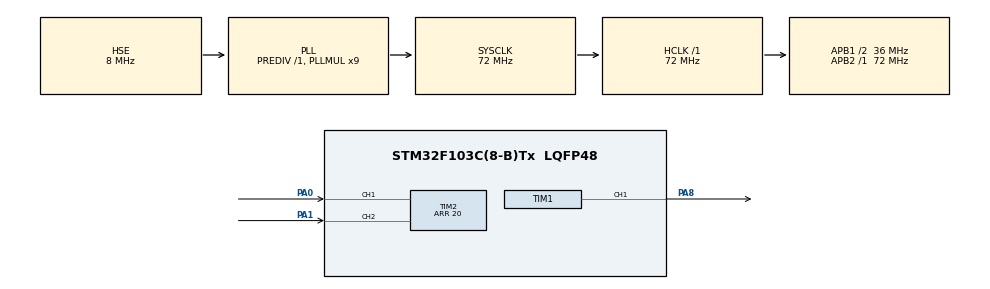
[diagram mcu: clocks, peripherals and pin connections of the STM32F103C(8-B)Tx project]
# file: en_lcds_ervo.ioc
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Mcu.Family=STM32F1
Mcu.Name=STM32F103C(8-B)Tx
Mcu.Package=LQFP48
NVIC.PriorityGroup=NVIC_PRIORITYGROUP_4
PA0-WKUP.Signal=S_TIM2_CH1_ETR
PA1.Signal=S_TIM2_CH2
PA13.Mode=Serial_Wire
PA13.Signal=SYS_JTMS-SWDIO
PA14.Mode=Serial_Wire
PA14.Signal=SYS_JTCK-SWCLK
PA8.Signal=S_TIM1_CH1
PD0-OSC_IN.Mode=HSE-External-Oscillator
PD0-OSC_IN.Signal=RCC_OSC_IN
PD1-OSC_OUT.Mode=HSE-External-Oscillator
PD1-OSC_OUT.Signal=RCC_OSC_OUT
ProjectManager.HeapSize=0x200
ProjectManager.StackSize=0x400
ProjectManager.TargetToolchain=STM32CubeIDE
RCC.AHBFreq_Value=72000000
RCC.APB1CLKDivider=RCC_HCLK_DIV2
RCC.APB1Freq_Value=36000000
RCC.APB1TimFreq_Value=72000000
RCC.APB2Freq_Value=72000000
RCC.APB2TimFreq_Value=72000000
RCC.HCLKFreq_Value=72000000
RCC.PLLMUL=RCC_PLL_MUL9
RCC.PLLSourceVirtual=RCC_PLLSOURCE_HSE
RCC.SYSCLKFreq_VALUE=72000000
RCC.SYSCLKSource=RCC_SYSCLKSOURCE_PLLCLK
RCC.USBFreq_Value=72000000
SH.S_TIM1_CH1.0=TIM1_CH1,PWM Generation1 CH1
SH.S_TIM2_CH1_ETR.0=TIM2_CH1,Encoder_Interface
SH.S_TIM2_CH2.0=TIM2_CH2,Encoder_Interface
TIM1.AutoReloadPreload=TIM_AUTORELOAD_PRELOAD_DISABLE
TIM1.Channel-PWM\ Generation1\ CH1=TIM_CHANNEL_1
TIM1.Period=19999
TIM1.Prescaler=72
TIM2.AutoReloadPreload=TIM_AUTORELOAD_PRELOAD_ENABLE
TIM2.EncoderMode=TIM_ENCODERMODE_TI1
TIM2.IC1Filter=10
TIM2.Period=20
VP_TIM1_VS_ClockSourceINT.Mode=Internal
board=custom

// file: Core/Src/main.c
/* USER CODE BEGIN Header */
/**
  ******************************************************************************
  * @file           : main.c
  * @brief          : Main program body
  ******************************************************************************
  * @attention
  *
  * Copyright (c) 2024 STMicroelectronics.
  * All rights reserved.
  *
  * This software is licensed under terms that can be found in the LICENSE file
  * in the root directory of this software component.
  * If no LICENSE file comes with this software, it is provided AS-IS.
  *
  ******************************************************************************
  */
/* USER CODE END Header */
#include "main.h"
#include <stdio.h>

/* USER CODE BEGIN PD */
#define counts_per_rev 20 //as we have 20 ticks in encoder and make the arr in ioc 20
/* USER CODE END PD */

TIM_HandleTypeDef htim1;
TIM_HandleTypeDef htim2;

/* USER CODE BEGIN PV */
Alcd_t lcd1 = {
		.Data_GPIO = GPIOA,
		.Data_GPIO_Start_Pin=2,
		.RS_GPIO= GPIOA,
		.RS_GPIO_Pin= GPIO_PIN_6,
		.EN_GPIO= GPIOA,
		.EN_GPIO_Pin= GPIO_PIN_7,
};
char degree_counter[20];
/* USER CODE END PV */

void SystemClock_Config(void);
static void MX_GPIO_Init(void);
static void MX_TIM1_Init(void);
static void MX_TIM2_Init(void);

/* USER CODE BEGIN 0 */
uint32_t degree_pwm(uint8_t degree_value );

/* USER CODE END 0 */

int main(void)
{

  /* MCU Configuration--------------------------------------------------------*/

  /* Reset of all peripherals, Initializes the Flash interface and the Systick. */
  HAL_Init();

  /* Configure the system clock */
  SystemClock_Config();

  /* Initialize all configured peripherals */
  MX_GPIO_Init();
  MX_TIM1_Init();
  MX_TIM2_Init();
  /* USER CODE BEGIN 2 */
  ///////************lcd config*****************
  Alcd_Init(&lcd1, 2, 0);
 // Alcd_PutAt(&lcd1,1,0,"HAzEM");
  Alcd_PutAt_n(&lcd1, 0, 0, "kiroo", Str_Len("kiroo"));
 // Alcd_Clear(&lcd1);
  ////////********encoder and servo config**************
    HAL_TIM_Encoder_Start(&htim2, TIM_CHANNEL_ALL); // Start the counter for the encoder
    HAL_TIM_PWM_Start(&htim1, TIM_CHANNEL_1); // For output to the servo
    __HAL_TIM_SET_COMPARE(&htim1, TIM_CHANNEL_1, 1500); // Set a duty cycle for the servo
    HAL_Delay(3000);

  /* USER CODE END 2 */

  /* Infinite loop */
  /* USER CODE BEGIN WHILE */
    while (1)
    {
        uint8_t encoder_counter = __HAL_TIM_GET_COUNTER(&htim2); // Get the counter of the encoder
        uint8_t degrees= (encoder_counter*180.0)/counts_per_rev;

        uint32_t pwm_val = degree_pwm(degrees); // Convert degrees to PWM value
        sprintf(degree_counter, "the angle %d", degrees);
          Alcd_PutAt_n(&lcd1, 0, 0,degree_counter , strlen(degree_counter));

       // __HAL_TIM_SET_COMPARE(&htim1, TIM_CHANNEL_1, pwm_val); // Set PWM value for servo
        htim1.Instance->CCR1 = pwm_val;
        HAL_Delay(100); // Delay for stability
        Alcd_Clear(&lcd1);
    }
    /* USER CODE END WHILE */

}

void SystemClock_Config(void)
{
  RCC_OscInitTypeDef RCC_OscInitStruct = {0};
  RCC_ClkInitTypeDef RCC_ClkInitStruct = {0};

  /** Initializes the RCC Oscillators according to the specified parameters
  * in the RCC_OscInitTypeDef structure.
  */
  RCC_OscInitStruct.OscillatorType = RCC_OSCILLATORTYPE_HSE;
  RCC_OscInitStruct.HSEState = RCC_HSE_ON;
  RCC_OscInitStruct.HSEPredivValue = RCC_HSE_PREDIV_DIV1;
  RCC_OscInitStruct.HSIState = RCC_HSI_ON;
  RCC_OscInitStruct.PLL.PLLState = RCC_PLL_ON;
  RCC_OscInitStruct.PLL.PLLSource = RCC_PLLSOURCE_HSE;
  RCC_OscInitStruct.PLL.PLLMUL = RCC_PLL_MUL9;
  if (HAL_RCC_OscConfig(&RCC_OscInitStruct) != HAL_OK)
  {
    Error_Handler();
  }

  /** Initializes the CPU, AHB and APB buses clocks
  */
  RCC_ClkInitStruct.ClockType = RCC_CLOCKTYPE_HCLK|RCC_CLOCKTYPE_SYSCLK
                              |RCC_CLOCKTYPE_PCLK1|RCC_CLOCKTYPE_PCLK2;
  RCC_ClkInitStruct.SYSCLKSource = RCC_SYSCLKSOURCE_PLLCLK;
  RCC_ClkInitStruct.AHBCLKDivider = RCC_SYSCLK_DIV1;
  RCC_ClkInitStruct.APB1CLKDivider = RCC_HCLK_DIV2;
  RCC_ClkInitStruct.APB2CLKDivider = RCC_HCLK_DIV1;

  if (HAL_RCC_ClockConfig(&RCC_ClkInitStruct, FLASH_LATENCY_2) != HAL_OK)
  {
    Error_Handler();
  }
}

static void MX_TIM1_Init(void)
{

  TIM_ClockConfigTypeDef sClockSourceConfig = {0};
  TIM_MasterConfigTypeDef sMasterConfig = {0};
  TIM_OC_InitTypeDef sConfigOC = {0};
  TIM_BreakDeadTimeConfigTypeDef sBreakDeadTimeConfig = {0};

  htim1.Instance = TIM1;
  htim1.Init.Prescaler = 72;
  htim1.Init.CounterMode = TIM_COUNTERMODE_UP;
  htim1.Init.Period = 19999;
  htim1.Init.ClockDivision = TIM_CLOCKDIVISION_DIV1;
  htim1.Init.RepetitionCounter = 0;
  htim1.Init.AutoReloadPreload = TIM_AUTORELOAD_PRELOAD_DISABLE;
  if (HAL_TIM_Base_Init(&htim1) != HAL_OK)
  {
    Error_Handler();
  }
  sClockSourceConfig.ClockSource = TIM_CLOCKSOURCE_INTERNAL;
  if (HAL_TIM_ConfigClockSource(&htim1, &sClockSourceConfig) != HAL_OK)
  {
    Error_Handler();
  }
  if (HAL_TIM_PWM_Init(&htim1) != HAL_OK)
  {
    Error_Handler();
  }
  sMasterConfig.MasterOutputTrigger = TIM_TRGO_RESET;
  sMasterConfig.MasterSlaveMode = TIM_MASTERSLAVEMODE_DISABLE;
  if (HAL_TIMEx_MasterConfigSynchronization(&htim1, &sMasterConfig) != HAL_OK)
  {
    Error_Handler();
  }
  sConfigOC.OCMode = TIM_OCMODE_PWM1;
  sConfigOC.Pulse = 0;
  sConfigOC.OCPolarity = TIM_OCPOLARITY_HIGH;
  sConfigOC.OCNPolarity = TIM_OCNPOLARITY_HIGH;
  sConfigOC.OCFastMode = TIM_OCFAST_DISABLE;
  sConfigOC.OCIdleState = TIM_OCIDLESTATE_RESET;
  sConfigOC.OCNIdleState = TIM_OCNIDLESTATE_RESET;
  if (HAL_TIM_PWM_ConfigChannel(&htim1, &sConfigOC, TIM_CHANNEL_1) != HAL_OK)
  {
    Error_Handler();
  }
  sBreakDeadTimeConfig.OffStateRunMode = TIM_OSSR_DISABLE;
  sBreakDeadTimeConfig.OffStateIDLEMode = TIM_OSSI_DISABLE;
  sBreakDeadTimeConfig.LockLevel = TIM_LOCKLEVEL_OFF;
  sBreakDeadTimeConfig.DeadTime = 0;
  sBreakDeadTimeConfig.BreakState = TIM_BREAK_DISABLE;
  sBreakDeadTimeConfig.BreakPolarity = TIM_BREAKPOLARITY_HIGH;
  sBreakDeadTimeConfig.AutomaticOutput = TIM_AUTOMATICOUTPUT_DISABLE;
  if (HAL_TIMEx_ConfigBreakDeadTime(&htim1, &sBreakDeadTimeConfig) != HAL_OK)
  {
    Error_Handler();
  }
  HAL_TIM_MspPostInit(&htim1);

}

static void MX_TIM2_Init(void)
{

  TIM_Encoder_InitTypeDef sConfig = {0};
  TIM_MasterConfigTypeDef sMasterConfig = {0};

  htim2.Instance = TIM2;
  htim2.Init.Prescaler = 0;
  htim2.Init.CounterMode = TIM_COUNTERMODE_UP;
  htim2.Init.Period = 20;
  htim2.Init.ClockDivision = TIM_CLOCKDIVISION_DIV1;
  htim2.Init.AutoReloadPreload = TIM_AUTORELOAD_PRELOAD_ENABLE;
  sConfig.EncoderMode = TIM_ENCODERMODE_TI1;
  sConfig.IC1Polarity = TIM_ICPOLARITY_RISING;
  sConfig.IC1Selection = TIM_ICSELECTION_DIRECTTI;
  sConfig.IC1Prescaler = TIM_ICPSC_DIV1;
  sConfig.IC1Filter = 10;
  sConfig.IC2Polarity = TIM_ICPOLARITY_RISING;
  sConfig.IC2Selection = TIM_ICSELECTION_DIRECTTI;
  sConfig.IC2Prescaler = TIM_ICPSC_DIV1;
  sConfig.IC2Filter = 0;
  if (HAL_TIM_Encoder_Init(&htim2, &sConfig) != HAL_OK)
  {
    Error_Handler();
  }
  sMasterConfig.MasterOutputTrigger = TIM_TRGO_RESET;
  sMasterConfig.MasterSlaveMode = TIM_MASTERSLAVEMODE_DISABLE;
  if (HAL_TIMEx_MasterConfigSynchronization(&htim2, &sMasterConfig) != HAL_OK)
  {
    Error_Handler();
  }

}

static void MX_GPIO_Init(void)
{

  /* GPIO Ports Clock Enable */
  __HAL_RCC_GPIOD_CLK_ENABLE();
  __HAL_RCC_GPIOA_CLK_ENABLE();

}

/* USER CODE BEGIN 4 */
/*uint32_t degree_pwm(uint32_t degree_value ){
	return ((degree_value*1000)/180)+1000;
};*/
uint32_t degree_pwm(uint8_t degree_value) {
    // Clamp the degree value to the range -90 to 90
   /* if (degree_value < -90) degree_value = -90;
    if (degree_value > 90) degree_value = 90;*/

    // Calculate PWM value based on the adjusted degrees
    return ((degree_value+90) * (1000.0 / 180)) + 1000;
}
/* USER CODE END 4 */

void Error_Handler(void)
{
  __disable_irq();
  while (1)
  {
  }
}
